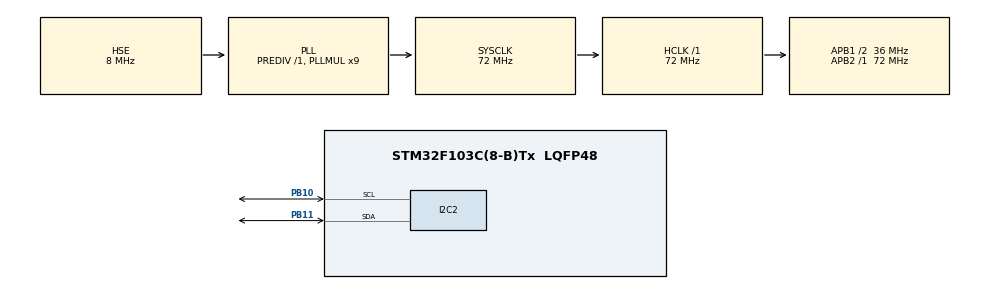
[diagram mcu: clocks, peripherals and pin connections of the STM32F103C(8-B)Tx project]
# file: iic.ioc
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Mcu.Family=STM32F1
Mcu.Name=STM32F103C(8-B)Tx
Mcu.Package=LQFP48
NVIC.PriorityGroup=NVIC_PRIORITYGROUP_4
PA13.Mode=Serial_Wire
PA13.Signal=SYS_JTMS-SWDIO
PA14.Mode=Serial_Wire
PA14.Signal=SYS_JTCK-SWCLK
PB10.Mode=I2C
PB10.Signal=I2C2_SCL
PB11.Mode=I2C
PB11.Signal=I2C2_SDA
PD0-OSC_IN.Mode=HSE-External-Oscillator
PD0-OSC_IN.Signal=RCC_OSC_IN
PD1-OSC_OUT.Mode=HSE-External-Oscillator
PD1-OSC_OUT.Signal=RCC_OSC_OUT
ProjectManager.HeapSize=0x200
ProjectManager.StackSize=0x400
ProjectManager.TargetToolchain=MDK-ARM V5.32
RCC.AHBFreq_Value=72000000
RCC.APB1CLKDivider=RCC_HCLK_DIV2
RCC.APB1Freq_Value=36000000
RCC.APB1TimFreq_Value=72000000
RCC.APB2Freq_Value=72000000
RCC.APB2TimFreq_Value=72000000
RCC.HCLKFreq_Value=72000000
RCC.PLLMUL=RCC_PLL_MUL9
RCC.PLLSourceVirtual=RCC_PLLSOURCE_HSE
RCC.SYSCLKFreq_VALUE=72000000
RCC.SYSCLKSource=RCC_SYSCLKSOURCE_PLLCLK
RCC.USBFreq_Value=72000000
board=custom

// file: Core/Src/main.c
/* USER CODE BEGIN Header */
/**
  ******************************************************************************
  * @file           : main.c
  * @brief          : Main program body
  ******************************************************************************
  * @attention
  *
  * Copyright (c) 2026 STMicroelectronics.
  * All rights reserved.
  *
  * This software is licensed under terms that can be found in the LICENSE file
  * in the root directory of this software component.
  * If no LICENSE file comes with this software, it is provided AS-IS.
  *
  ******************************************************************************
  */
/* USER CODE END Header */
#include "main.h"
#include "i2c.h"
#include "gpio.h"

/* USER CODE BEGIN Includes */
#include "OLED.h"
/* USER CODE END Includes */

/* USER CODE BEGIN PD */
#define	MPU6050_ACCEL_XOUT_H	0x3B
#define	MPU6050_ACCEL_XOUT_L	0x3C
#define	MPU6050_ACCEL_YOUT_H	0x3D
#define	MPU6050_ACCEL_YOUT_L	0x3E
#define	MPU6050_ACCEL_ZOUT_H	0x3F
#define	MPU6050_ACCEL_ZOUT_L	0x40
#define	MPU6050_TEMP_OUT_H		0x41
#define	MPU6050_TEMP_OUT_L		0x42
#define	MPU6050_GYRO_XOUT_H		0x43
#define	MPU6050_GYRO_XOUT_L		0x44
#define	MPU6050_GYRO_YOUT_H		0x45
#define	MPU6050_GYRO_YOUT_L		0x46
#define	MPU6050_GYRO_ZOUT_H		0x47
#define	MPU6050_GYRO_ZOUT_L		0x48

#define	MPU6050_PWR_MGMT_1		0x6B
#define	MPU6050_PWR_MGMT_2		0x6C
#define	MPU6050_WHO_AM_I		0x75
/* USER CODE END PD */

/* USER CODE BEGIN PV */
uint8_t buf[6];
/* USER CODE END PV */

void SystemClock_Config(void);

int main(void)
{

  /* MCU Configuration--------------------------------------------------------*/

  /* Reset of all peripherals, Initializes the Flash interface and the Systick. */
  HAL_Init();

  /* Configure the system clock */
  SystemClock_Config();

  /* Initialize all configured peripherals */
  MX_GPIO_Init();
  MX_I2C2_Init();
  /* USER CODE BEGIN 2 */
  	OLED_Init();
	int16_t temp;
	uint8_t i,data;
	uint8_t temp0;
	data = 0x00;
	HAL_I2C_Mem_Write(&hi2c2, 0xD0, MPU6050_PWR_MGMT_1, I2C_MEMADD_SIZE_8BIT, &data, 1, 100);
    HAL_I2C_Mem_Read(&hi2c2,0xD0,MPU6050_WHO_AM_I,I2C_MEMADD_SIZE_8BIT,&temp0,1,100);
	OLED_ShowHexNum(1,1,temp0,5);
	OLED_ShowString(1,1,"ax:");
	OLED_ShowString(2,1,"ay:");
	OLED_ShowString(3,1,"az:");
	HAL_Delay(100);
  /* USER CODE END 2 */

  /* Infinite loop */
  while (1)
  {

    /* USER CODE BEGIN 3 */
	  HAL_I2C_Mem_Read(&hi2c2,0xD0,MPU6050_ACCEL_XOUT_H,I2C_MEMADD_SIZE_8BIT,buf,6,100);
	  for(i=0;i<3;i++)
	  {
		  temp=(buf[2*i]<<8);
		  temp=temp | buf[1+2*i];
		  OLED_ShowSignedNum(i+1,4,temp,5);
	  }
	  HAL_Delay(100);
  }
  /* USER CODE END 3 */
}

void SystemClock_Config(void)
{
  RCC_OscInitTypeDef RCC_OscInitStruct = {0};
  RCC_ClkInitTypeDef RCC_ClkInitStruct = {0};

  /** Initializes the RCC Oscillators according to the specified parameters
  * in the RCC_OscInitTypeDef structure.
  */
  RCC_OscInitStruct.OscillatorType = RCC_OSCILLATORTYPE_HSE;
  RCC_OscInitStruct.HSEState = RCC_HSE_ON;
  RCC_OscInitStruct.HSEPredivValue = RCC_HSE_PREDIV_DIV1;
  RCC_OscInitStruct.HSIState = RCC_HSI_ON;
  RCC_OscInitStruct.PLL.PLLState = RCC_PLL_ON;
  RCC_OscInitStruct.PLL.PLLSource = RCC_PLLSOURCE_HSE;
  RCC_OscInitStruct.PLL.PLLMUL = RCC_PLL_MUL9;
  if (HAL_RCC_OscConfig(&RCC_OscInitStruct) != HAL_OK)
  {
    Error_Handler();
  }

  /** Initializes the CPU, AHB and APB buses clocks
  */
  RCC_ClkInitStruct.ClockType = RCC_CLOCKTYPE_HCLK|RCC_CLOCKTYPE_SYSCLK
                              |RCC_CLOCKTYPE_PCLK1|RCC_CLOCKTYPE_PCLK2;
  RCC_ClkInitStruct.SYSCLKSource = RCC_SYSCLKSOURCE_PLLCLK;
  RCC_ClkInitStruct.AHBCLKDivider = RCC_SYSCLK_DIV1;
  RCC_ClkInitStruct.APB1CLKDivider = RCC_HCLK_DIV2;
  RCC_ClkInitStruct.APB2CLKDivider = RCC_HCLK_DIV1;

  if (HAL_RCC_ClockConfig(&RCC_ClkInitStruct, FLASH_LATENCY_2) != HAL_OK)
  {
    Error_Handler();
  }
}

void Error_Handler(void)
{
  __disable_irq();
  while (1)
  {
  }
}
